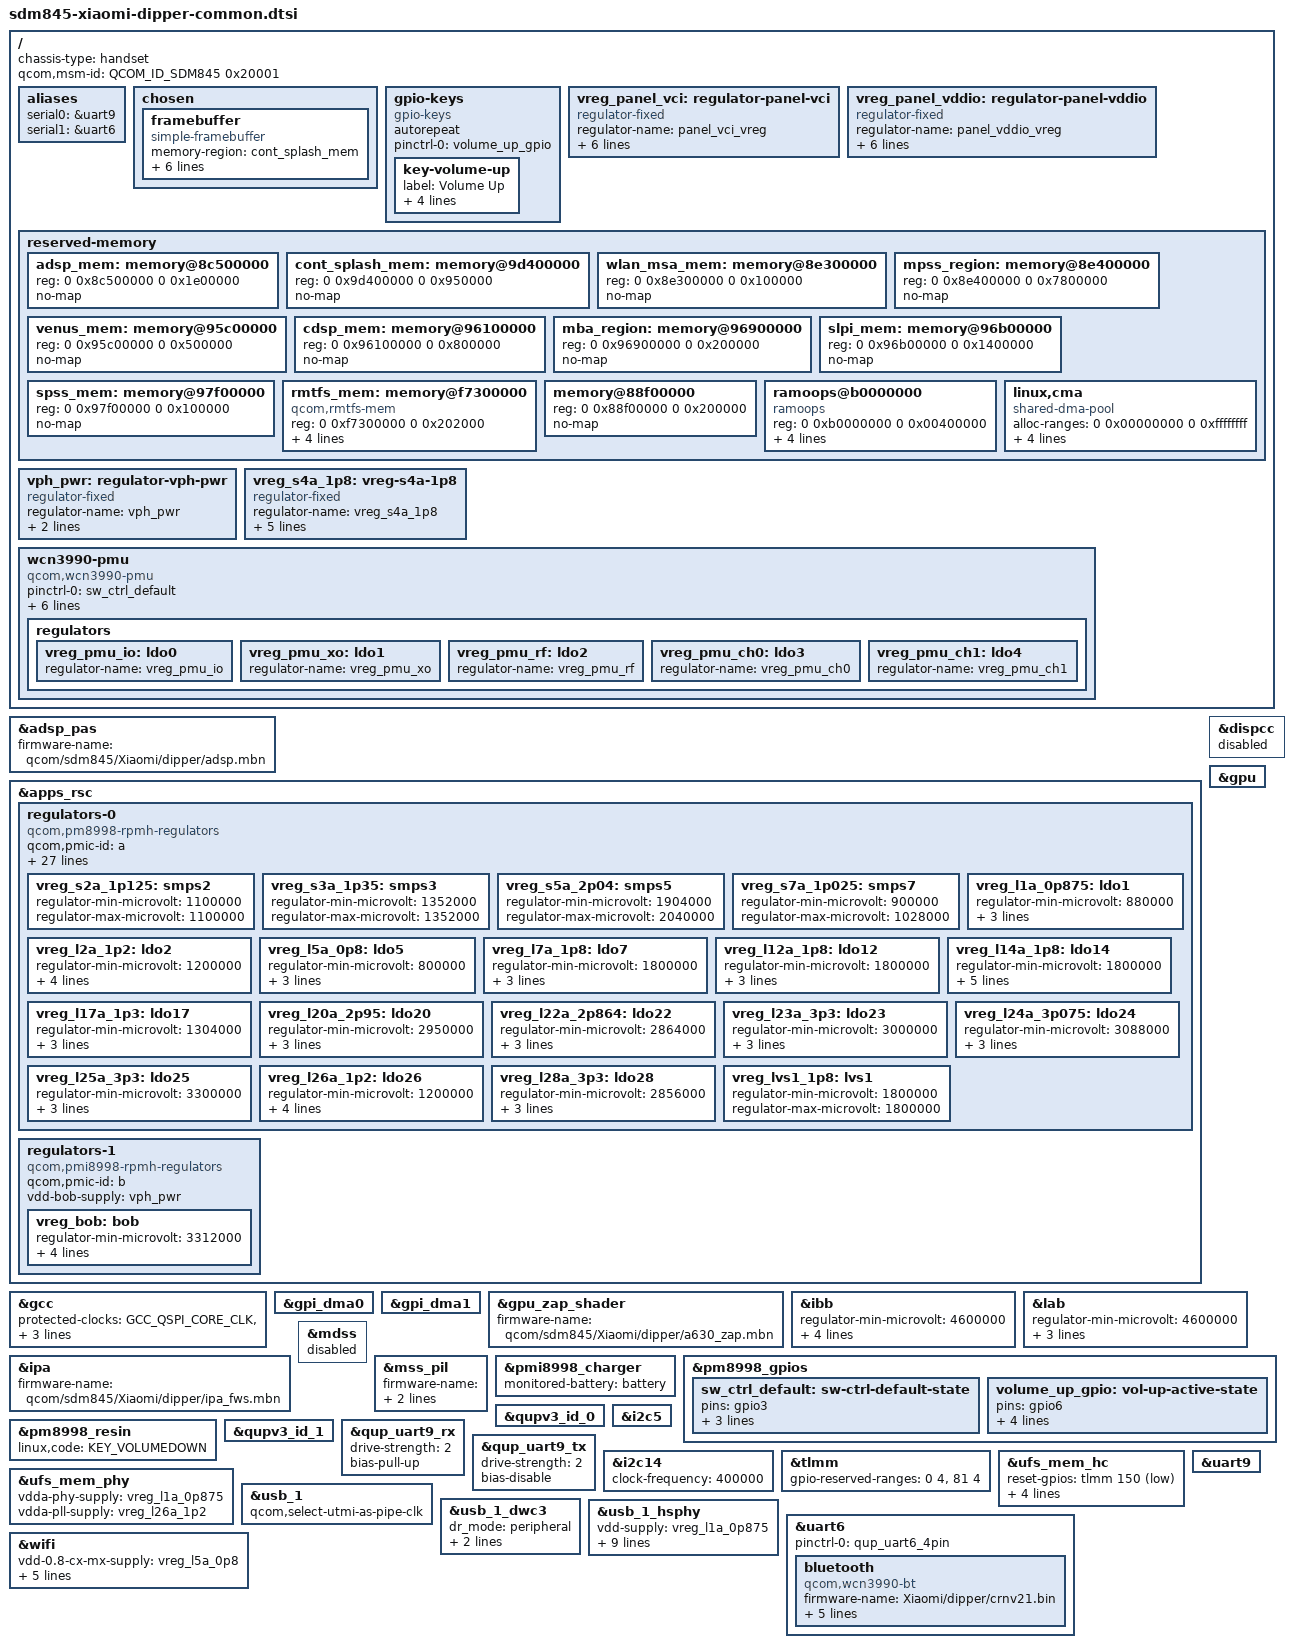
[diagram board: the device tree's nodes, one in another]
// SPDX-License-Identifier: GPL-2.0-only
/*
 * Xiaomi Mi 8 family common device tree source.
 * Covers Mi 8 Explorer Edition (equuleus), Mi 8 (dipper), Mi 8 Pro (urza).
 *
 * Copyright David Heidelberg. All rights reserved.
 */

/dts-v1/;

#include <dt-bindings/arm/qcom,ids.h>
#include <dt-bindings/firmware/qcom,scm.h>
#include <dt-bindings/gpio/gpio.h>
#include <dt-bindings/input/linux-event-codes.h>
#include <dt-bindings/interrupt-controller/irq.h>
#include <dt-bindings/phy/phy-qcom-qusb2.h>
#include <dt-bindings/regulator/qcom,rpmh-regulator.h>
#include "sdm845.dtsi"
#include "pm8998.dtsi"
#include "pmi8998.dtsi"

/delete-node/ &adsp_mem;
/delete-node/ &cdsp_mem;
/delete-node/ &mba_region;
/delete-node/ &mpss_region;
/delete-node/ &rmtfs_mem;
/delete-node/ &slpi_mem;
/delete-node/ &spss_mem;
/delete-node/ &tz_mem;
/delete-node/ &venus_mem;
/delete-node/ &wlan_msa_mem;

/ {
	chassis-type = "handset";

	qcom,msm-id = <QCOM_ID_SDM845 0x20001>;

	aliases {
		serial0 = &uart9;
		serial1 = &uart6;
	};

	chosen {
		#address-cells = <2>;
		#size-cells = <2>;
		ranges;

		framebuffer {
			compatible = "simple-framebuffer";
			memory-region = <&cont_splash_mem>;

			vci-supply = <&vreg_panel_vci>;
			vddio-supply = <&vreg_panel_vddio>;

			width = <1080>;
			height = <2248>;
			stride = <(1080 * 4)>;
			format = "a8r8g8b8";
		};
	};

	gpio-keys {
		compatible = "gpio-keys";
		autorepeat;

		pinctrl-0 = <&volume_up_gpio>;
		pinctrl-names = "default";

		key-volume-up {
			label = "Volume Up";
			linux,code = <KEY_VOLUMEUP>;
			gpios = <&pm8998_gpios 6 GPIO_ACTIVE_LOW>;
			wakeup-source;
			debounce-interval = <15>;
		};
	};

	vreg_panel_vci: regulator-panel-vci {
		compatible = "regulator-fixed";
		regulator-name = "panel_vci_vreg";

		regulator-min-microvolt = <3000000>;
		regulator-max-microvolt = <3000000>;

		gpio = <&tlmm 35 GPIO_ACTIVE_HIGH>;
		enable-active-high;
		startup-delay-us = <4000>;
		regulator-boot-on;
	};

	vreg_panel_vddio: regulator-panel-vddio {
		compatible = "regulator-fixed";
		regulator-name = "panel_vddio_vreg";

		regulator-min-microvolt = <1800000>;
		regulator-max-microvolt = <1800000>;

		gpio = <&tlmm 23 GPIO_ACTIVE_HIGH>;
		enable-active-high;
		startup-delay-us = <4000>;
		regulator-boot-on;
	};

	reserved-memory {
		adsp_mem: memory@8c500000 {
			reg = <0 0x8c500000 0 0x1e00000>;
			no-map;
		};

		cont_splash_mem: memory@9d400000 {
			reg = <0 0x9d400000 0 0x950000>;
			no-map;
		};

		wlan_msa_mem: memory@8e300000 {
			reg = <0 0x8e300000 0 0x100000>;
			no-map;
		};

		mpss_region: memory@8e400000 {
			reg = <0 0x8e400000 0 0x7800000>;
			no-map;
		};

		venus_mem: memory@95c00000 {
			reg = <0 0x95c00000 0 0x500000>;
			no-map;
		};

		cdsp_mem: memory@96100000 {
			reg = <0 0x96100000 0 0x800000>;
			no-map;
		};

		mba_region: memory@96900000 {
			reg = <0 0x96900000 0 0x200000>;
			no-map;
		};

		slpi_mem: memory@96b00000 {
			reg = <0 0x96b00000 0 0x1400000>;
			no-map;
		};

		spss_mem: memory@97f00000 {
			reg = <0 0x97f00000 0 0x100000>;
			no-map;
		};

		rmtfs_mem: memory@f7300000 {
			compatible = "qcom,rmtfs-mem";
			reg = <0 0xf7300000 0 0x202000>;
			qcom,use-guard-pages;
			no-map;

			qcom,client-id = <1>;
			qcom,vmid = <QCOM_SCM_VMID_MSS_MSA>;
		};

		/* bootloader reserves this range for its own use. */
		memory@88f00000 {
			reg = <0 0x88f00000 0 0x200000>;
			no-map;
		};

		ramoops@b0000000 {
			compatible = "ramoops";
			reg = <0 0xb0000000 0 0x00400000>;
			record-size = <0x40000>;
			console-size = <0x40000>;
			ftrace-size = <0x40000>;
			pmsg-size = <0x200000>;
		};

		linux,cma {
			compatible = "shared-dma-pool";
			alloc-ranges = <0 0x00000000 0 0xffffffff>;
			reusable;
			alignment = <0 0x400000>;
			size = <0 0x2c00000>;
			linux,cma-default;
		};
	};

	vph_pwr: regulator-vph-pwr {
		compatible = "regulator-fixed";
		regulator-name = "vph_pwr";

		regulator-min-microvolt = <3700000>;
		regulator-max-microvolt = <3700000>;
	};

	vreg_s4a_1p8: vreg-s4a-1p8 {
		compatible = "regulator-fixed";
		regulator-name = "vreg_s4a_1p8";

		regulator-min-microvolt = <1800000>;
		regulator-max-microvolt = <1800000>;
		regulator-always-on;
		regulator-boot-on;

		vin-supply = <&vph_pwr>;
	};

	wcn3990-pmu {
		compatible = "qcom,wcn3990-pmu";

		pinctrl-0 = <&sw_ctrl_default>;
		pinctrl-names = "default";

		vddio-supply = <&vreg_s4a_1p8>;
		vddxo-supply = <&vreg_l7a_1p8>;
		vddrf-supply = <&vreg_l17a_1p3>;
		vddch0-supply = <&vreg_l25a_3p3>;
		vddch1-supply = <&vreg_l23a_3p3>;

		swctrl-gpios = <&pm8998_gpios 3 GPIO_ACTIVE_HIGH>;

		regulators {
			vreg_pmu_io: ldo0 {
				regulator-name = "vreg_pmu_io";
			};

			vreg_pmu_xo: ldo1 {
				regulator-name = "vreg_pmu_xo";
			};

			vreg_pmu_rf: ldo2 {
				regulator-name = "vreg_pmu_rf";
			};

			vreg_pmu_ch0: ldo3 {
				regulator-name = "vreg_pmu_ch0";
			};

			vreg_pmu_ch1: ldo4 {
				regulator-name = "vreg_pmu_ch1";
			};
		};
	};
};

&adsp_pas {
	firmware-name = "qcom/sdm845/Xiaomi/dipper/adsp.mbn";

	status = "okay";
};

&apps_rsc {
	regulators-0 {
		compatible = "qcom,pm8998-rpmh-regulators";
		qcom,pmic-id = "a";

		vdd-s1-supply = <&vph_pwr>;
		vdd-s2-supply = <&vph_pwr>;
		vdd-s3-supply = <&vph_pwr>;
		vdd-s4-supply = <&vph_pwr>;
		vdd-s5-supply = <&vph_pwr>;
		vdd-s6-supply = <&vph_pwr>;
		vdd-s7-supply = <&vph_pwr>;
		vdd-s8-supply = <&vph_pwr>;
		vdd-s9-supply = <&vph_pwr>;
		vdd-s10-supply = <&vph_pwr>;
		vdd-s11-supply = <&vph_pwr>;
		vdd-s12-supply = <&vph_pwr>;
		vdd-s13-supply = <&vph_pwr>;
		vdd-l1-l27-supply = <&vreg_s7a_1p025>;
		vdd-l2-l8-l17-supply = <&vreg_s3a_1p35>;
		vdd-l3-l11-supply = <&vreg_s7a_1p025>;
		vdd-l4-l5-supply = <&vreg_s7a_1p025>;
		vdd-l6-supply = <&vph_pwr>;
		vdd-l7-l12-l14-l15-supply = <&vreg_s5a_2p04>;
		vdd-l9-supply = <&vreg_bob>;
		vdd-l10-l23-l25-supply = <&vreg_bob>;
		vdd-l13-l19-l21-supply = <&vreg_bob>;
		vdd-l16-l28-supply = <&vreg_bob>;
		vdd-l18-l22-supply = <&vreg_bob>;
		vdd-l20-l24-supply = <&vreg_bob>;
		vdd-l26-supply = <&vreg_s3a_1p35>;
		vin-lvs-1-2-supply = <&vreg_s4a_1p8>;

		vreg_s2a_1p125: smps2 {
			regulator-min-microvolt = <1100000>;
			regulator-max-microvolt = <1100000>;
		};

		vreg_s3a_1p35: smps3 {
			regulator-min-microvolt = <1352000>;
			regulator-max-microvolt = <1352000>;
		};

		vreg_s5a_2p04: smps5 {
			regulator-min-microvolt = <1904000>;
			regulator-max-microvolt = <2040000>;
		};

		vreg_s7a_1p025: smps7 {
			regulator-min-microvolt = <900000>;
			regulator-max-microvolt = <1028000>;
		};

		vreg_l1a_0p875: ldo1 {
			regulator-min-microvolt = <880000>;
			regulator-max-microvolt = <880000>;
			regulator-initial-mode = <RPMH_REGULATOR_MODE_HPM>;
		};

		vreg_l2a_1p2: ldo2 {
			regulator-min-microvolt = <1200000>;
			regulator-max-microvolt = <1200000>;
			regulator-initial-mode = <RPMH_REGULATOR_MODE_HPM>;
			regulator-always-on;
		};

		vreg_l5a_0p8: ldo5 {
			regulator-min-microvolt = <800000>;
			regulator-max-microvolt = <800000>;
			regulator-initial-mode = <RPMH_REGULATOR_MODE_HPM>;
		};

		vreg_l7a_1p8: ldo7 {
			regulator-min-microvolt = <1800000>;
			regulator-max-microvolt = <1800000>;
			regulator-initial-mode = <RPMH_REGULATOR_MODE_HPM>;
		};

		vreg_l12a_1p8: ldo12 {
			regulator-min-microvolt = <1800000>;
			regulator-max-microvolt = <1800000>;
			regulator-initial-mode = <RPMH_REGULATOR_MODE_HPM>;
		};

		vreg_l14a_1p8: ldo14 {
			regulator-min-microvolt = <1800000>;
			regulator-max-microvolt = <1800000>;
			regulator-initial-mode = <RPMH_REGULATOR_MODE_HPM>;
			regulator-boot-on;
			regulator-always-on;
		};

		vreg_l17a_1p3: ldo17 {
			regulator-min-microvolt = <1304000>;
			regulator-max-microvolt = <1304000>;
			regulator-initial-mode = <RPMH_REGULATOR_MODE_HPM>;
		};

		vreg_l20a_2p95: ldo20 {
			regulator-min-microvolt = <2950000>;
			regulator-max-microvolt = <2960000>;
			regulator-initial-mode = <RPMH_REGULATOR_MODE_HPM>;
		};

		vreg_l22a_2p864: ldo22 {
			regulator-min-microvolt = <2864000>;
			regulator-max-microvolt = <2864000>;
			regulator-initial-mode = <RPMH_REGULATOR_MODE_HPM>;
		};

		vreg_l23a_3p3: ldo23 {
			regulator-min-microvolt = <3000000>;
			regulator-max-microvolt = <3312000>;
			regulator-initial-mode = <RPMH_REGULATOR_MODE_HPM>;
		};

		vreg_l24a_3p075: ldo24 {
			regulator-min-microvolt = <3088000>;
			regulator-max-microvolt = <3088000>;
			regulator-initial-mode = <RPMH_REGULATOR_MODE_HPM>;
		};

		vreg_l25a_3p3: ldo25 {
			regulator-min-microvolt = <3300000>;
			regulator-max-microvolt = <3312000>;
			regulator-initial-mode = <RPMH_REGULATOR_MODE_HPM>;
		};

		vreg_l26a_1p2: ldo26 {
			regulator-min-microvolt = <1200000>;
			regulator-max-microvolt = <1200000>;
			regulator-initial-mode = <RPMH_REGULATOR_MODE_HPM>;
			regulator-boot-on;
		};

		vreg_l28a_3p3: ldo28 {
			regulator-min-microvolt = <2856000>;
			regulator-max-microvolt = <3008000>;
			regulator-initial-mode = <RPMH_REGULATOR_MODE_HPM>;
		};

		vreg_lvs1_1p8: lvs1 {
			regulator-min-microvolt = <1800000>;
			regulator-max-microvolt = <1800000>;
		};
	};

	regulators-1 {
		compatible = "qcom,pmi8998-rpmh-regulators";
		qcom,pmic-id = "b";

		vdd-bob-supply = <&vph_pwr>;

		vreg_bob: bob {
			regulator-min-microvolt = <3312000>;
			regulator-max-microvolt = <3600000>;
			regulator-initial-mode = <RPMH_REGULATOR_MODE_AUTO>;
			regulator-allow-bypass;
		};
	};
};

&dispcc {
	/* Disable for now so simple-framebuffer continues working */
	status = "disabled";
};

&gcc {
	protected-clocks = <GCC_QSPI_CORE_CLK>,
			   <GCC_QSPI_CORE_CLK_SRC>,
			   <GCC_QSPI_CNOC_PERIPH_AHB_CLK>,
			   <GCC_LPASS_Q6_AXI_CLK>,
			   <GCC_LPASS_SWAY_CLK>;
};

&gpi_dma0 {
	status = "okay";
};

&gpi_dma1 {
	status = "okay";
};

&gpu {
	status = "okay";
};

&gpu_zap_shader {
	firmware-name = "qcom/sdm845/Xiaomi/dipper/a630_zap.mbn";
};

&ibb {
	regulator-min-microvolt = <4600000>;
	regulator-max-microvolt = <6000000>;
	regulator-over-current-protection;
	regulator-pull-down;
	regulator-soft-start;
};

&ipa {
	firmware-name = "qcom/sdm845/Xiaomi/dipper/ipa_fws.mbn";

	status = "okay";
};

&lab {
	regulator-min-microvolt = <4600000>;
	regulator-max-microvolt = <6000000>;
	regulator-pull-down;
	regulator-soft-start;
};

&mdss {
	/* Disable for now so simple-framebuffer continues working */
	status = "disabled";
};

&mss_pil {
	firmware-name = "qcom/sdm845/Xiaomi/dipper/mba.mbn",
			"qcom/sdm845/Xiaomi/dipper/modem.mbn";

	status = "okay";
};

&pmi8998_charger {
	monitored-battery = <&battery>;

	status = "okay";
};

&pm8998_gpios {
	sw_ctrl_default: sw-ctrl-default-state {
		pins = "gpio3";
		function = "normal";
		input-enable;
		bias-pull-down;
	};

	volume_up_gpio: vol-up-active-state {
		pins = "gpio6";
		function = "normal";
		input-enable;
		bias-pull-up;
		power-source = <0>;
	};
};

&pm8998_resin {
	linux,code = <KEY_VOLUMEDOWN>;

	status = "okay";
};

&qupv3_id_0 {
	status = "okay";
};

&qupv3_id_1 {
	status = "okay";
};

&qup_uart9_rx {
	drive-strength = <2>;
	bias-pull-up;
};

&qup_uart9_tx {
	drive-strength = <2>;
	bias-disable;
};

&i2c5 {
	status = "okay";

	/* tas2557 @4c */
};

&i2c14 {
	clock-frequency = <400000>;

	status = "okay";

	/* stmfts5 @49 */
};

&tlmm {
	gpio-reserved-ranges = < 0 4>, /* SPI (Goodix Fingerprint) */
			       <81 4>; /* SPI (Synaptics Fingerprint) */
};

&ufs_mem_hc {
	reset-gpios = <&tlmm 150 GPIO_ACTIVE_LOW>;

	vcc-supply = <&vreg_l20a_2p95>;
	vcc-max-microamp = <600000>;
	vccq2-supply = <&vreg_s4a_1p8>;
	vccq2-max-microamp = <600000>;

	status = "okay";

};

&ufs_mem_phy {
	vdda-phy-supply = <&vreg_l1a_0p875>;
	vdda-pll-supply = <&vreg_l26a_1p2>;

	status = "okay";
};

&usb_1 {
	qcom,select-utmi-as-pipe-clk;

	status = "okay";
};

&usb_1_dwc3 {
	/* Until we have Type C hooked up we'll force this as peripheral. */
	dr_mode = "peripheral";

	maximum-speed = "high-speed";
	phys = <&usb_1_hsphy>;
	phy-names = "usb2-phy";
};

&usb_1_hsphy {
	vdd-supply = <&vreg_l1a_0p875>;
	vdda-pll-supply = <&vreg_l12a_1p8>;
	vdda-phy-dpdm-supply = <&vreg_l24a_3p075>;

	qcom,imp-res-offset-value = <8>;
	qcom,hstx-trim-value = <QUSB2_V2_HSTX_TRIM_21_6_MA>;
	qcom,preemphasis-level = <QUSB2_V2_PREEMPHASIS_5_PERCENT>;
	qcom,preemphasis-width = <QUSB2_V2_PREEMPHASIS_WIDTH_HALF_BIT>;

	status = "okay";
};

&uart6 {
	pinctrl-0 = <&qup_uart6_4pin>;

	status = "okay";

	bluetooth {
		compatible = "qcom,wcn3990-bt";

		/*
		 * This path is relative to the qca/
		 * subdir under lib/firmware.
		 */
		firmware-name = "Xiaomi/dipper/crnv21.bin";

		vddio-supply = <&vreg_pmu_io>;
		vddxo-supply = <&vreg_pmu_xo>;
		vddrf-supply = <&vreg_pmu_rf>;
		vddch0-supply = <&vreg_pmu_ch0>;

		max-speed = <3200000>;
	};
};

&uart9 {
	status = "okay";
};

&wifi {
	vdd-0.8-cx-mx-supply = <&vreg_l5a_0p8>;
	vdd-1.8-xo-supply = <&vreg_pmu_xo>;
	vdd-1.3-rfa-supply = <&vreg_pmu_rf>;
	vdd-3.3-ch0-supply = <&vreg_pmu_ch0>;
	vdd-3.3-ch1-supply = <&vreg_pmu_ch1>;

	qcom,snoc-host-cap-skip-quirk;

	status = "okay";
};
